# MCXN947_cm33_core0 register map
Vendor: nxp.com; File version: 1.0
CPU: CM33 r2p0, little endian, MPU, FPU, VTOR, 3 interrupt priority bits
Registers are 32-bit, read-write, reset 0x0 unless marked. A register's access mark holds for its fields unless they carry their own. Offsets are from the block's base; [hi:lo] are bit positions; {n}, {i} and the like mark numbered series.

## PINT0 — Pin Interrupts and Pattern Match
Base 0x40004000
0x00 ISEL — Pin Interrupt Mode
  [7:0] PMODE — Interrupt mode
    0=ISEL_0 (In bit n configures the interrupt to be edge-sensitive); 1=ISEL_1 (In bit n configures the interrupt to be level-sensitive)
0x04 IENR — Pin Interrupt Level or Rising-Edge Interrupt Enable
  [7:0] ENRL — Enables Interrupt
    0=In bit n disables the corresponding interrupt; 1=In bit n enables the corresponding interrupt
0x08 SIENR wo reset not defined write-1-sets — Pin Interrupt Level or Rising-Edge Interrupt Set
  [7:0] SETENRL write-1-sets — Configures IENR
    0=No operation for interrupt n; 1=Enable rising edge or level interrupt for interrupt n
0x0C CIENR reset not defined write-1-clears — Pin Interrupt Level (Rising-Edge Interrupt) Clear
  [7:0] CENRL write-1-clears — Clear bits in IENR
    0=No operation; 1=Disable rising edge or level interrupt
0x10 IENF — Pin Interrupt Active Level or Falling-Edge Interrupt Enable
  [7:0] ENAF — Enables Interrupt
    0=Disable (set active interrupt level LOW); 1=Enable (set active interrupt level HIGH)
0x14 SIENF wo reset not defined write-1-sets — Pin Interrupt Active Level or Falling-Edge Interrupt Set
  [7:0] SETENAF write-1-sets — Write 1 to this address to clear to disable interrupts. Bit a sets bit n in IENF.
    0=Writes 0 to IENF; 1=Select HIGH-active interrupt or enable falling-edge interrupt
0x18 CIENF wo reset not defined — Pin Interrupt Active Level or Falling-Edge Interrupt Clear
  [7:0] CENAF — Writes 0 to IENF
    0=No operation; 1=LOW-active interrupt selected or falling-edge interrupt disabled
0x1C RISE — Pin Interrupt Rising Edge
  [7:0] RDET — Rising-Edge Detect
    0=Read 0- No rising edge (since Reset or you wrote a 1 to this field last time), Write 0- No operation; 1=Read 1- Rising edge (since Reset or you wrote a 1 to this field last time), Write 1- Clear rising-edge detection for this pin
0x20 FALL — Pin Interrupt Falling Edge
  [7:0] FDET — Falling-Edge Detect
    0=Read 0- No falling edge (since Reset or you wrote a 1 to this field last time), Write 0- No operation; 1=Read 1- Falling edge (since Reset or you wrote a 1 to this field last time), Write 1- Clear falling-edge detection for this bit
0x24 IST — Pin Interrupt Status
  [7:0] PSTAT
    0=Read 0- Interrupt is not requested, Write 0- No operation; 1=Read 1- Interrupt is requested, Write 1 (edge-sensitive)- clear rising- and falling-edge detection for this pin, Write 1 (level-sensitive)- switch the active level for this pin in
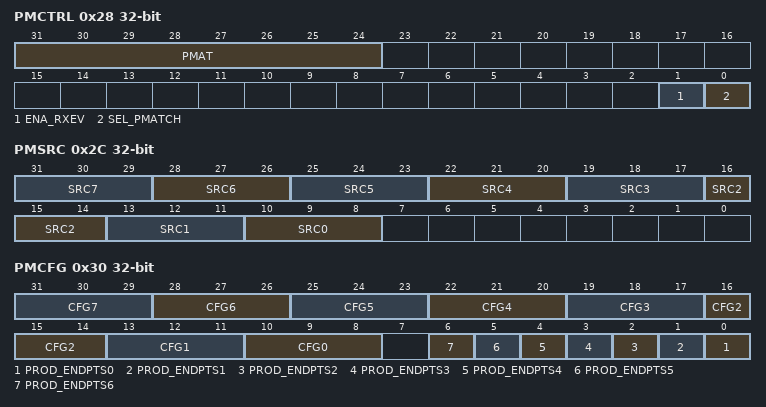
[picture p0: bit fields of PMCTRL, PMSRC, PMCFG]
0x28 PMCTRL — Pattern-Match Interrupt Control
  [31:24] PMAT ro — Pattern Matches
    1=The corresponding product term is matched by the current state of the appropriate inputs
  [1] ENA_RXEV — Enables the RXEV output to the CPU and/or to a GPIO output, when the specified Boolean expression evaluates to true. If this value is 0b, RXEV output to the CPU is disabled. If this value is 1b, RXEV output to the CPU is enabled.
    0=DISABLED; 1=ENABLED
  [0] SEL_PMATCH — Specifies whether the pin interrupts are controlled by the pin interrupt function or by the pattern-match function. If this value is 0b, interrupts are driven in response to the standard pin interrupt function. If this value is 1b, interrupts are driven in response to pattern matches.
    0=PIN_INTERRUPT; 1=PATTERN_MATCH
0x2C PMSRC — Pattern-Match Interrupt Bit-Slice Source
  [all] fields
    {v}=INPUT{v} (Input {v} (selects the pin identified in PINT_SEL{v})) (v=0..7)
  [3n+10:3n+8] SRC{n} (n=0..7) — Selects the input source for bit slice {n}
0x30 PMCFG — Pattern-Match Interrupt Bit Slice Configuration
  [3n+10:3n+8] CFG{n} (n=0..7) — Match Configuration
    0=CONSTANT_HIGH; 1=STICKY_RISING_EDGE; 2=STICKY_FALLING_EDGE; 3=STICKY_RISING_FALLING_EDGE (Sticky rising or falling edge); 4=HIGH_LEVEL; 5=LOW_LEVEL; 6=CONSTANT_ZERO (Constant 0); 7=EVENT (Event (Nonsticky rising or falling edge))
  [n] PROD_ENDPTS{n} (n=0..6) — Determines whether slice {n} is an endpoint. Slice {n} is not an endpoint. Slice {n} is the endpoint of a product term (minterm). Pin interrupt {n} in the NVIC is raised if the minterm evaluates as true.
    0=NO_EFFECT; 1=ENDPOINT
